# BL702 register map
Vendor: Bouffalo Lab; Series: WiFi BT; File version: 1.0
Registers are 32-bit, read-write, reset 0x0 unless marked. A register's access mark holds for its fields unless they carry their own. Offsets are from the block's base; [hi:lo] are bit positions; {n}, {i} and the like mark numbered series.

## SPI — SPI master/slave control
Base 0x4000A200
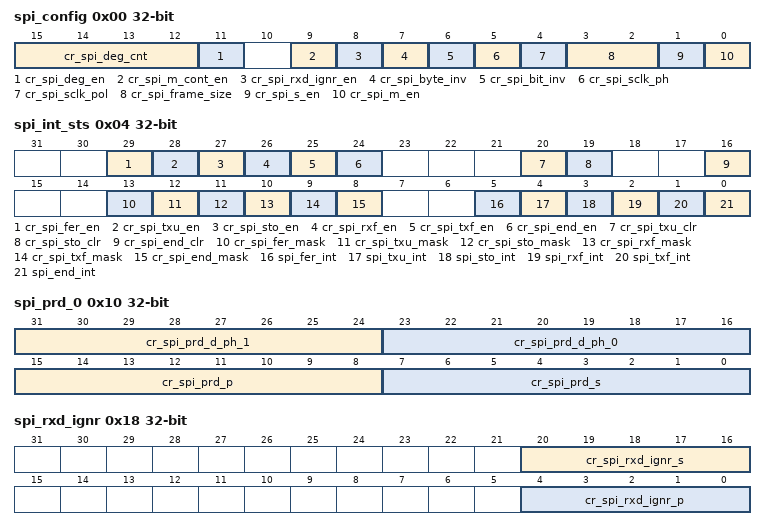
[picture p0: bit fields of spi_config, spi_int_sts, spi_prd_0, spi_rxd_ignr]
0x00 spi_config
  [15:12] cr_spi_deg_cnt, [11] cr_spi_deg_en, [9] cr_spi_m_cont_en, [8] cr_spi_rxd_ignr_en, [7] cr_spi_byte_inv, [6] cr_spi_bit_inv, [5] cr_spi_sclk_ph, [4] cr_spi_sclk_pol, [3:2] cr_spi_frame_size, [1] cr_spi_s_en, [0] cr_spi_m_en
0x04 spi_int_sts
  [29] cr_spi_fer_en, [28] cr_spi_txu_en, [27] cr_spi_sto_en, [26] cr_spi_rxf_en, [25] cr_spi_txf_en, [24] cr_spi_end_en, [20] cr_spi_txu_clr, [19] cr_spi_sto_clr, [16] cr_spi_end_clr, [13] cr_spi_fer_mask, [12] cr_spi_txu_mask, [11] cr_spi_sto_mask, [10] cr_spi_rxf_mask, [9] cr_spi_txf_mask, [8] cr_spi_end_mask, [5] spi_fer_int, [4] spi_txu_int, [3] spi_sto_int, [2] spi_rxf_int, [1] spi_txf_int, [0] spi_end_int
0x08 spi_bus_busy
  [0] sts_spi_bus_busy
0x10 spi_prd_0
  [31:24] cr_spi_prd_d_ph_1, [23:16] cr_spi_prd_d_ph_0, [15:8] cr_spi_prd_p, [7:0] cr_spi_prd_s
0x14 spi_prd_1
  [7:0] cr_spi_prd_i
0x18 spi_rxd_ignr
  [20:16] cr_spi_rxd_ignr_s, [4:0] cr_spi_rxd_ignr_p
0x1C spi_sto_value
  [11:0] cr_spi_sto_value
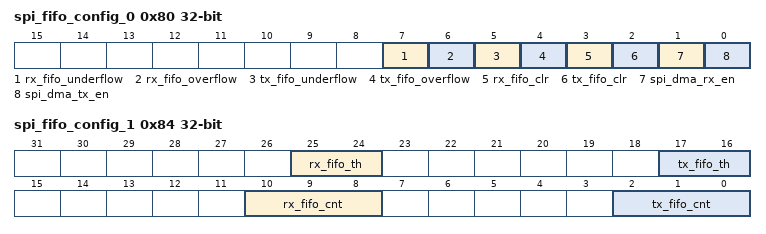
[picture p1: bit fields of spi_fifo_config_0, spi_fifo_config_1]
0x80 spi_fifo_config_0
  [7] rx_fifo_underflow, [6] rx_fifo_overflow, [5] tx_fifo_underflow, [4] tx_fifo_overflow, [3] rx_fifo_clr, [2] tx_fifo_clr, [1] spi_dma_rx_en, [0] spi_dma_tx_en
0x84 spi_fifo_config_1
  [25:24] rx_fifo_th, [17:16] tx_fifo_th, [10:8] rx_fifo_cnt, [2:0] tx_fifo_cnt
0x88 spi_fifo_wdata
0x8C spi_fifo_rdata

## I2C — I2C control
Base 0x4000A300
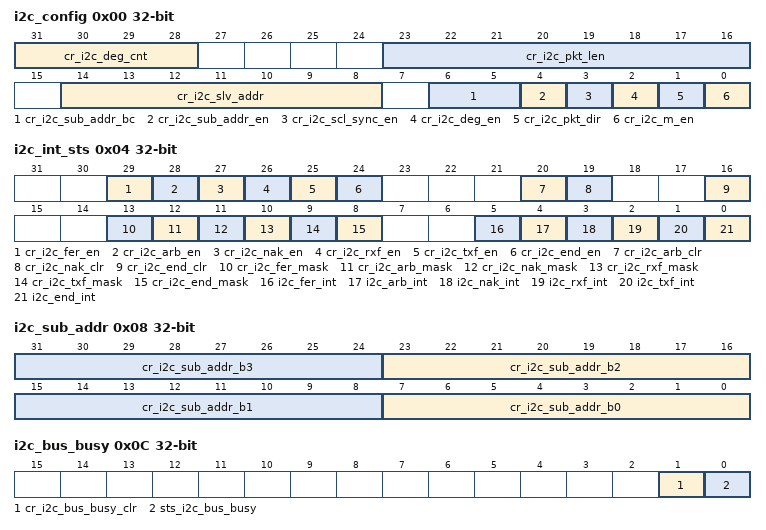
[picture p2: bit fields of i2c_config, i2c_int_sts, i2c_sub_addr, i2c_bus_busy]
0x00 i2c_config
  [31:28] cr_i2c_deg_cnt, [23:16] cr_i2c_pkt_len, [14:8] cr_i2c_slv_addr, [6:5] cr_i2c_sub_addr_bc, [4] cr_i2c_sub_addr_en, [3] cr_i2c_scl_sync_en, [2] cr_i2c_deg_en, [1] cr_i2c_pkt_dir, [0] cr_i2c_m_en
0x04 i2c_int_sts
  [29] cr_i2c_fer_en, [28] cr_i2c_arb_en, [27] cr_i2c_nak_en, [26] cr_i2c_rxf_en, [25] cr_i2c_txf_en, [24] cr_i2c_end_en, [20] cr_i2c_arb_clr, [19] cr_i2c_nak_clr, [16] cr_i2c_end_clr, [13] cr_i2c_fer_mask, [12] cr_i2c_arb_mask, [11] cr_i2c_nak_mask, [10] cr_i2c_rxf_mask, [9] cr_i2c_txf_mask, [8] cr_i2c_end_mask, [5] i2c_fer_int, [4] i2c_arb_int, [3] i2c_nak_int, [2] i2c_rxf_int, [1] i2c_txf_int, [0] i2c_end_int
0x08 i2c_sub_addr
  [8n+7:8n] cr_i2c_sub_addr_b{n} (n=0..3)
0x0C i2c_bus_busy
  [1] cr_i2c_bus_busy_clr, [0] sts_i2c_bus_busy
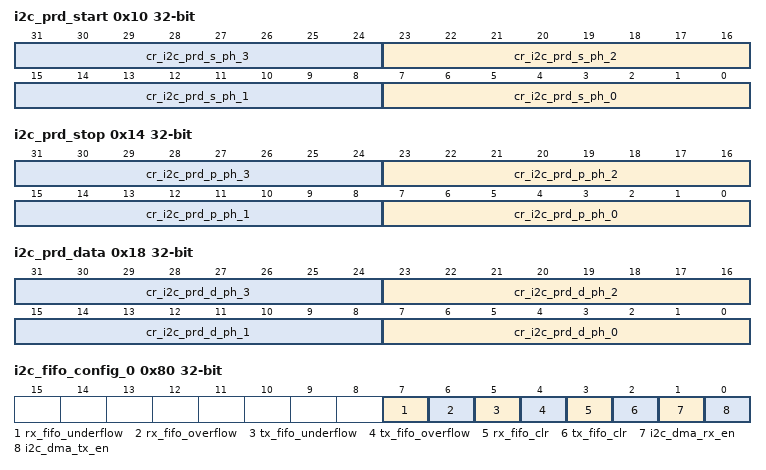
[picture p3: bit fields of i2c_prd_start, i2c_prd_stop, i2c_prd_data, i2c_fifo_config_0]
0x10 i2c_prd_start
  [8n+7:8n] cr_i2c_prd_s_ph_{n} (n=0..3)
0x14 i2c_prd_stop
  [8n+7:8n] cr_i2c_prd_p_ph_{n} (n=0..3)
0x18 i2c_prd_data
  [8n+7:8n] cr_i2c_prd_d_ph_{n} (n=0..3)
0x80 i2c_fifo_config_0
  [7] rx_fifo_underflow, [6] rx_fifo_overflow, [5] tx_fifo_underflow, [4] tx_fifo_overflow, [3] rx_fifo_clr, [2] tx_fifo_clr, [1] i2c_dma_rx_en, [0] i2c_dma_tx_en
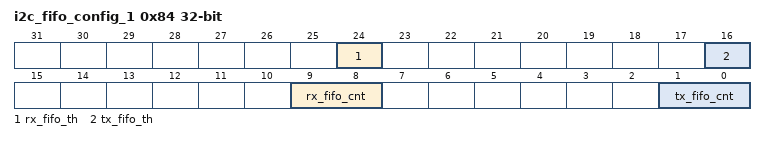
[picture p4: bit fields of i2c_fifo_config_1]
0x84 i2c_fifo_config_1
  [24] rx_fifo_th, [16] tx_fifo_th, [9:8] rx_fifo_cnt, [1:0] tx_fifo_cnt
0x88 i2c_fifo_wdata
0x8C i2c_fifo_rdata

## PWM — Pulse Width Modulation *5 control
Base 0x4000A400
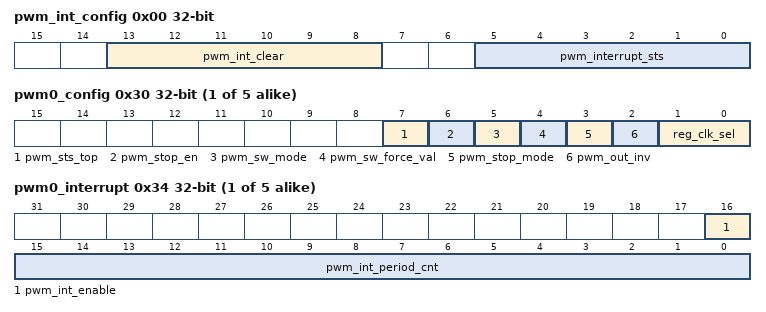
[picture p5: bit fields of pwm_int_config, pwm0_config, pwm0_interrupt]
0x00 pwm_int_config
  [13:8] pwm_int_clear, [5:0] pwm_interrupt_sts
{0x20+0x20*i} pwm{i}_clkdiv (i=0..4)
  [15:0] pwm_clk_div
{0x24+0x20*i} pwm{i}_thre1 (i=0..4)
  [15:0] pwm_thre1
{0x28+0x20*i} pwm{i}_thre2 (i=0..4)
  [15:0] pwm_thre2
{0x2C+0x20*i} pwm{i}_period (i=0..4)
  [15:0] pwm_period
{0x30+0x20*i} pwm{i}_config (i=0..4)
  [7] pwm_sts_top, [6] pwm_stop_en, [5] pwm_sw_mode, [4] pwm_sw_force_val, [3] pwm_stop_mode, [2] pwm_out_inv, [1:0] reg_clk_sel
{0x34+0x20*i} pwm{i}_interrupt (i=0..4)
  [16] pwm_int_enable, [15:0] pwm_int_period_cnt

## TIMER — Timer control
Base 0x4000A500
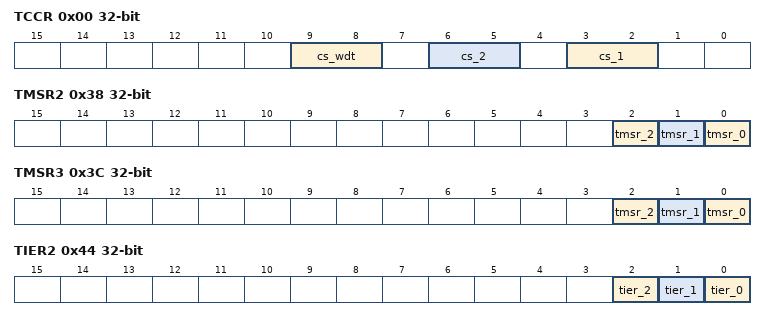
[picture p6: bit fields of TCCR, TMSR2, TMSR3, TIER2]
0x00 TCCR
  [9:8] cs_wdt, [6:5] cs_2, [3:2] cs_1
{0x10+4i} TMR2_{i} (i=0..2)
  [31:0] tmr
{0x1C+4i} TMR3_{i} (i=0..2)
  [31:0] tmr
0x2C TCR2
  [31:0] tcr
0x30 TCR3
  [31:0] tcr
0x38 TMSR2
  [2] tmsr_2, [1] tmsr_1, [0] tmsr_0
0x3C TMSR3
  [2] tmsr_2, [1] tmsr_1, [0] tmsr_0
0x44 TIER2
  [2] tier_2, [1] tier_1, [0] tier_0
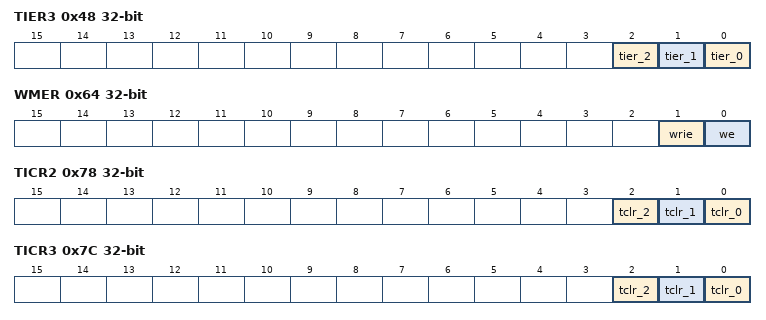
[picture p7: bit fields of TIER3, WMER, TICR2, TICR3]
0x48 TIER3
  [2] tier_2, [1] tier_1, [0] tier_0
0x50 TPLVR2
  [31:0] tplvr
0x54 TPLVR3
  [31:0] tplvr
0x5C TPLCR2
  [1:0] tplcr
0x60 TPLCR3
  [1:0] tplcr
0x64 WMER
  [1] wrie, [0] we
0x68 WMR
  [15:0] wmr
0x6C WVR
  [15:0] wvr
0x70 WSR
  [0] wts
0x78 TICR2
  [2] tclr_2, [1] tclr_1, [0] tclr_0
0x7C TICR3
  [2] tclr_2, [1] tclr_1, [0] tclr_0
0x80 WICR
  [0] wiclr
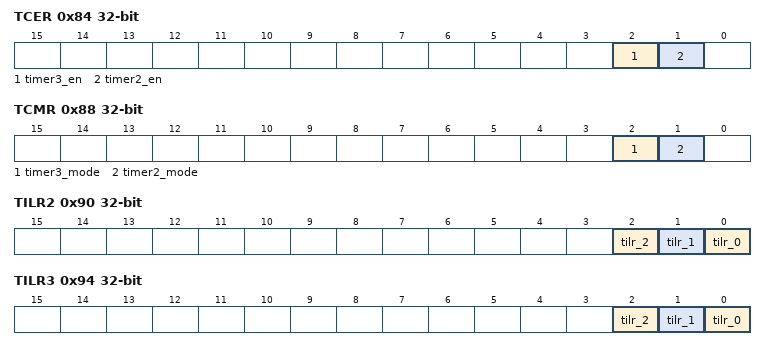
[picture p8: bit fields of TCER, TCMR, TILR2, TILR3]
0x84 TCER
  [2] timer3_en, [1] timer2_en
0x88 TCMR
  [2] timer3_mode, [1] timer2_mode
0x90 TILR2
  [2] tilr_2, [1] tilr_1, [0] tilr_0
0x94 TILR3
  [2] tilr_2, [1] tilr_1, [0] tilr_0
0x98 WCR
  [0] wcr
0x9C WFAR
  [15:0] wfar
0xA0 WSAR
  [15:0] wsar
0xA8 TCVWR2
  [31:0] tcvwr
0xAC TCVWR3
  [31:0] tcvwr
0xB4 TCVSYN2
0xB8 TCVSYN3
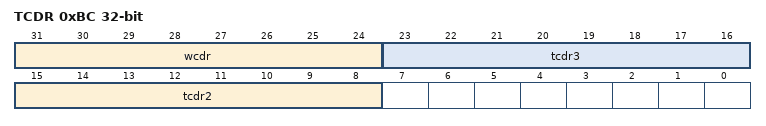
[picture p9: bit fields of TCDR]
0xBC TCDR
  [31:24] wcdr, [23:16] tcdr3, [15:8] tcdr2
